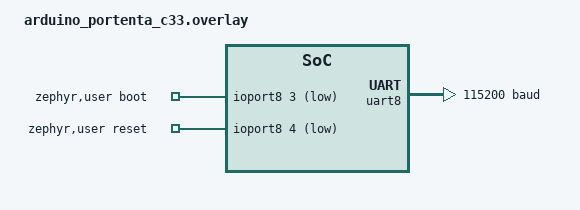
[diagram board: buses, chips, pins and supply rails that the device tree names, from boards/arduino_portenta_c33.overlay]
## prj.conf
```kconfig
CONFIG_UART_CONSOLE=y
CONFIG_CONSOLE=y
CONFIG_LOG=y
CONFIG_LOG_DEFAULT_LEVEL=3
CONFIG_LOG_BACKEND_UART=y
CONFIG_LOG_BACKEND_UART_AUTOSTART=y

CONFIG_USB_DEVICE_STACK_NEXT=y

CONFIG_SERIAL=y
CONFIG_UART_LINE_CTRL=y
CONFIG_UART_USE_RUNTIME_CONFIGURE=y
CONFIG_USBD_CDC_ACM_CLASS=y
CONFIG_CDC_ACM_SERIAL_INITIALIZE_AT_BOOT=n

CONFIG_SAMPLE_USBD_PID=0x0001
CONFIG_SAMPLE_USBD_PRODUCT="USBD CDC ACM bridge sample"
```

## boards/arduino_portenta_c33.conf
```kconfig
# Drive the ESP32-C3 boot/reset straps from the CDC DTR/RTS lines.
CONFIG_GPIO=y

# Reliable flashing throughput: large USB request and bridge buffers so
# bursts from esptool are not dropped.
CONFIG_UDC_BUF_POOL_SIZE=4096
CONFIG_UART_BRIDGE_BUF_SIZE=4096
```

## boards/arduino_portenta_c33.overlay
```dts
/*
 * Copyright (C) Arduino s.r.l. and/or its affiliated companies
 *
 * SPDX-License-Identifier: Apache-2.0
 *
 * cdc_acm_bridge on Arduino Portenta C33: flash the onboard ESP32-C3
 * coprocessor from a host esptool over USB CDC-ACM.
 *
 * Bridges USB CDC-ACM <-> SCI8 (the ESP32-C3 UART) and drives the ESP boot
 * (P803, GPIO0/download strap) and reset/EN (P804) pins from the CDC DTR/RTS
 * lines, reproducing esptool's auto-download-reset circuit. The normal SPI
 * esp-hosted WiFi, the BT HCI link, and the download-strap regulator are
 * disabled so the UART and those pins are free for flashing.
 *
 * A boards/<board>.overlay replaces the sample's app.overlay, so the bridge and
 * CDC-ACM nodes are declared here too (reusing the board's board_cdc_acm_uart).
 */

#include <zephyr/dt-bindings/gpio/gpio.h>

/ {
	uart-bridge0 {
		compatible = "zephyr,uart-bridge";
		peers = <&board_cdc_acm_uart &uart8>;
	};

	zephyr,user {
		/* boot <- DTR, reset <- RTS; active-low (esptool default_reset).
		 *   boot-gpios  : P803 (ESP32-C3 GPIO0 / download strap)
		 *   reset-gpios : P804 (ESP32-C3 EN / reset)
		 */
		boot-gpios = <&ioport8 3 GPIO_ACTIVE_LOW>;
		reset-gpios = <&ioport8 4 GPIO_ACTIVE_LOW>;
	};

	/* P803 is also the esp-hosted download-strap regulator; disable it so the
	 * boot line above is free.
	 */
	download-esp32 {
		status = "disabled";
	};
};

/* ESP UART becomes a plain bridge peer: no BT HCI, no hardware flow control.
 * The ESP32-C3 ROM bootloader expects 115200 on its UART during download.
 */
&uart8 {
	current-speed = <115200>;
	/delete-property/ hw-flow-control;
};

&bt_hci_uart {
	status = "disabled";
};

/* The sample does not use the main I2C buses; disabling them avoids the RA IIC
 * driver instantiating with a clock-frequency above the controller's supported
 * max-bitrate in the base Portenta C33 DTS.
 */
&iic0 {
	status = "disabled";
};

&iic1 {
	status = "disabled";
};

/* Disable the SPI WiFi so it does not claim the reset/handshake pins. */
&spi1 {
	esp_hosted@1 {
		status = "disabled";
	};
};

/* Full-speed is ample for flashing (bulk 64-byte, ~1 MB/s) and avoids a
 * high-speed bulk-IN device->host stall in the RA USBHS UDC.
 */
&usbhs {
	maximum-speed = "full-speed";
};
```

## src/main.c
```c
/*
 * Copyright 2025 Google LLC
 *
 * SPDX-License-Identifier: Apache-2.0
 */

#include <sample_usbd.h>

#include <stdio.h>
#include <string.h>
#include <zephyr/device.h>
#include <zephyr/drivers/gpio.h>
#include <zephyr/drivers/uart.h>
#include <zephyr/drivers/uart/uart_bridge.h>
#include <zephyr/kernel.h>

#include <zephyr/usb/usb_device.h>
#include <zephyr/usb/usbd.h>
#include <zephyr/logging/log.h>
LOG_MODULE_REGISTER(cdc_acm_bridge, LOG_LEVEL_INF);

static const struct gpio_dt_spec esp32_boot_gpio =
	GPIO_DT_SPEC_GET(DT_PATH(zephyr_user), boot_gpios);
static const struct gpio_dt_spec esp32_reset_gpio =
	GPIO_DT_SPEC_GET(DT_PATH(zephyr_user), reset_gpios);

struct esp32_download_state {
	bool dtr;
	bool rts;
	bool initialized;
};

static struct esp32_download_state esp32_state;

const struct device *const uart_dev = DEVICE_DT_GET_ONE(zephyr_cdc_acm_uart);

static struct usbd_context *sample_usbd;

#define DEVICE_DT_GET_COMMA(node_id) DEVICE_DT_GET(node_id),

const struct device *uart_bridges[] = {
	DT_FOREACH_STATUS_OKAY(zephyr_uart_bridge, DEVICE_DT_GET_COMMA)
};

static void esp32_apply_boot_reset_state(bool dtr, bool rts)
{
	/* ESP32-C3 GPIO0 and EN are active-low.  The USB CDC DTR/RTS state is
	 * interpreted as the reset/download sequence used by esptool:
	 *  - DTR=0, RTS=1 -> chip in reset (EN low, GPIO0 high)
	 *  - DTR=1, RTS=0 -> ROM download mode (GPIO0 low, EN high)
	 *  - DTR=0, RTS=0 -> idle / released
	 *
	 * The logical values passed to gpio_pin_set_dt() are the active-low values
	 * required by the board's GPIO_ACTIVE_LOW strap pins.
	 */
	bool boot_active = dtr;
	bool reset_active = rts;

	gpio_pin_set_dt(&esp32_boot_gpio, boot_active ? 1 : 0);
	gpio_pin_set_dt(&esp32_reset_gpio, reset_active ? 1 : 0);

	LOG_INF("ESP32 boot/reset: DTR=%d RTS=%d boot=%d reset=%d", dtr, rts,
		boot_active ? 1 : 0, reset_active ? 1 : 0);
}

static void esp32_set_boot_and_reset_from_line_state(const struct device *dev)
{
	uint32_t dtr = 0U;
	uint32_t rts = 0U;
	int ret;

	ret = uart_line_ctrl_get(dev, UART_LINE_CTRL_DTR, &dtr);
	if (ret != 0) {
		LOG_WRN("Failed to get UART DTR state: %d", ret);
		return;
	}

	ret = uart_line_ctrl_get(dev, UART_LINE_CTRL_RTS, &rts);
	if (ret != 0) {
		LOG_WRN("Failed to get UART RTS state: %d", ret);
		return;
	}

	if (!esp32_state.initialized ||
	    esp32_state.dtr != !!dtr ||
	    esp32_state.rts != !!rts) {
		esp32_state.dtr = !!dtr;
		esp32_state.rts = !!rts;
		esp32_state.initialized = true;

		/* Emulate the relevant esptool reset timing windows on the ESP strap
		 * pins so the ROM bootloader sees the same transitions the host is
		 * requesting.
		 */
		if (!esp32_state.dtr && esp32_state.rts) {
			esp32_apply_boot_reset_state(false, true);
			k_sleep(K_MSEC(100));
		} else if (esp32_state.dtr && !esp32_state.rts) {
			esp32_apply_boot_reset_state(true, false);
			k_sleep(K_MSEC(50));
		} else {
			esp32_apply_boot_reset_state(false, false);
		}
	}
}

static void sample_msg_cb(struct usbd_context *const ctx, const struct usbd_msg *msg)
{
	LOG_INF("USBD message: %s", usbd_msg_type_string(msg->type));

	if (usbd_can_detect_vbus(ctx)) {
		if (msg->type == USBD_MSG_VBUS_READY) {
			if (usbd_enable(ctx)) {
				LOG_ERR("Failed to enable device support");
			}
		}

		if (msg->type == USBD_MSG_VBUS_REMOVED) {
			if (usbd_disable(ctx)) {
				LOG_ERR("Failed to disable device support");
			}
		}
	}

	if (msg->type == USBD_MSG_CDC_ACM_LINE_CODING ||
	    msg->type == USBD_MSG_CDC_ACM_CONTROL_LINE_STATE) {
		for (uint8_t i = 0; i < ARRAY_SIZE(uart_bridges); i++) {
			/* update all bridges, non valid combinations are
			 * skipped automatically.
			 */
			uart_bridge_settings_update(msg->dev, uart_bridges[i]);
		}
	}

	if (msg->type == USBD_MSG_CDC_ACM_CONTROL_LINE_STATE) {
		esp32_set_boot_and_reset_from_line_state(msg->dev);
	}
}

int main(void)
{
	int err;

	if (!device_is_ready(esp32_boot_gpio.port) || !device_is_ready(esp32_reset_gpio.port)) {
		LOG_ERR("ESP32 boot/reset GPIO ports not ready");
		return -ENODEV;
	}

	err = gpio_pin_configure_dt(&esp32_boot_gpio, GPIO_OUTPUT_ACTIVE);
	if (err != 0) {
		LOG_ERR("Failed to configure ESP32 boot GPIO: %d", err);
		return err;
	}

	err = gpio_pin_configure_dt(&esp32_reset_gpio, GPIO_OUTPUT_ACTIVE);
	if (err != 0) {
		LOG_ERR("Failed to configure ESP32 reset GPIO: %d", err);
		return err;
	}

	esp32_state.dtr = false;
	esp32_state.rts = false;
	esp32_state.initialized = false;
	gpio_pin_set_dt(&esp32_boot_gpio, 0);
	gpio_pin_set_dt(&esp32_reset_gpio, 0);

	sample_usbd = sample_usbd_init_device(sample_msg_cb);
	if (sample_usbd == NULL) {
		LOG_ERR("Failed to initialize USB device");
		return -ENODEV;
	}

	if (!usbd_can_detect_vbus(sample_usbd)) {
		err = usbd_enable(sample_usbd);
		if (err) {
			LOG_ERR("Failed to enable device support");
			return err;
		}
	}

	LOG_INF("USB device support enabled");

	k_sleep(K_FOREVER);

	return 0;
}
```
